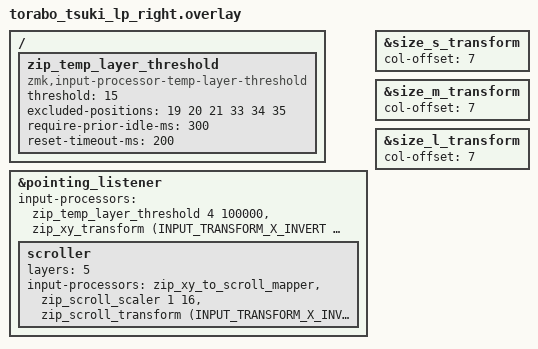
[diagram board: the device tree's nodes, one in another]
#include "torabo_tsuki_lp.dtsi"
#include <input/processors.dtsi>
#include <dt-bindings/zmk/input_transform.h>

/ {
    zip_temp_layer_threshold: zip_temp_layer_threshold {
        compatible = "zmk,input-processor-temp-layer-threshold";
        #input-processor-cells = <2>;

        // AML発動に必要な累積移動量
        threshold = <15>;

        // 以下で指定したキー以外を押すとAML解除
        excluded-positions = <
            19 // u
            20 // i
            21 // o
            33 // j
            34 // k
            35 // l
        >;

        // キー入力から300ms間はAMLを発動しない
        require-prior-idle-ms = <300>;

        // 蓄積された移動量をリセットするまでの時間
        reset-timeout-ms = <200>;
    };
};

&pointing_listener {
    input-processors = <
        &zip_temp_layer_threshold 4 100000
        &zip_xy_transform (INPUT_TRANSFORM_X_INVERT | INPUT_TRANSFORM_Y_INVERT)
    >;

    // SCROLLレイヤー(5)ではポインタ移動をスクロールに変換する
    scroller {
        layers = <5>;
        input-processors = <
            &zip_xy_to_scroll_mapper
            &zip_scroll_scaler 1 16
            &zip_scroll_transform (INPUT_TRANSFORM_X_INVERT | INPUT_TRANSFORM_Y_INVERT)
        >;
    };
};

&size_s_transform {
    col-offset = <7>;
};

&size_m_transform {
    col-offset = <7>;
};

&size_l_transform {
    col-offset = <7>;
};
